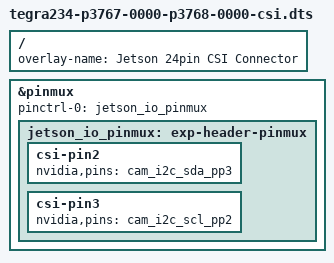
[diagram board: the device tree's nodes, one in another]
/*
 * Copyright (c) 2023, NVIDIA CORPORATION.  All rights reserved.
 *
 * This program is free software; you can redistribute it and/or modify it
 * under the terms and conditions of the GNU General Public License,
 * version 2, as published by the Free Software Foundation.
 *
 * This program is distributed in the hope it will be useful, but WITHOUT
 * ANY WARRANTY; without even the implied warranty of MERCHANTABILITY or
 * FITNESS FOR A PARTICULAR PURPOSE.  See the GNU General Public License for
 * more details.
 *
 * You should have received a copy of the GNU General Public License
 * along with this program.  If not, see <http://www.gnu.org/licenses/>.
 */

/*
 * Device-tree overlay for tegra234-p3767-0000-p3768-0000 CSI Camera Connector.
 */

/dts-v1/;
/plugin/;

#include <dt-bindings/pinctrl/pinctrl-tegra.h>
#include <dt-common/jetson/tegra234-p3767-0000-common.h>

/ {
	overlay-name = "Jetson 24pin CSI Connector";
	compatible = JETSON_COMPATIBLE_P3768;

	fragment@0 {
		target = <&pinmux>;
		__overlay__ {
			pinctrl-names = "default";
			pinctrl-0 = <&jetson_io_pinmux>;
			jetson_io_pinmux: exp-header-pinmux {
				csi-pin2 {
					nvidia,pins = "cam_i2c_sda_pp3";
				};
				csi-pin3 {
					nvidia,pins = "cam_i2c_scl_pp2";
				};
			};
		};
	};
};
